# ECAP_0 register map
Vendor: Texas Instruments
Peripheral module from a debugger description file (folder 66AK2G0x_66AK2G1x).
Registers are 32-bit, read-write, reset 0x0 unless marked. A register's access mark holds for its fields unless they carry their own. Offsets are as the file gives them; lines under a group give offsets from that group; [hi:lo] are bit positions; {n}, {i} and the like mark numbered series; 'fields as' and 'values as' point back to an identical list; <NAME> marks a mode.

## ECAP_0
0x00 PWMSS_ECAP_TSCNT
  [31:0] TSCNT — Active 32 bit-counter register that is used as the capture time-base
0x04 PWMSS_ECAP_CNTPHS
  [31:0] CNTPHS — Counter phase value register that can be programmed for phase lag/lead. This register shadows TSCNT and is loaded into
0x08 PWMSS_ECAP_CAP1
  [31:0] CAP1 — This register can be loaded (written) by the following.
0x0C PWMSS_ECAP_CAP2
  [31:0] CAP2 — This register can be loaded (written) by the following.
0x10 PWMSS_ECAP_CAP3
  [31:0] CAP3 — In CMP mode, this is a time-stamp capture register. In APWM mode, this is the period shadow (APRD) register. User SW updates the PWM period value through this register. In this mode, CAP3 shadows CAP1.
0x14 PWMSS_ECAP_CAP4
  [31:0] CAP4 — In CMP mode, this is a time-stamp capture register. In APWM mode, this is the compare shadow (ACMP) register. User SW updates the PWM compare value through this register. In this mode, CAP4 shadows CAP2.
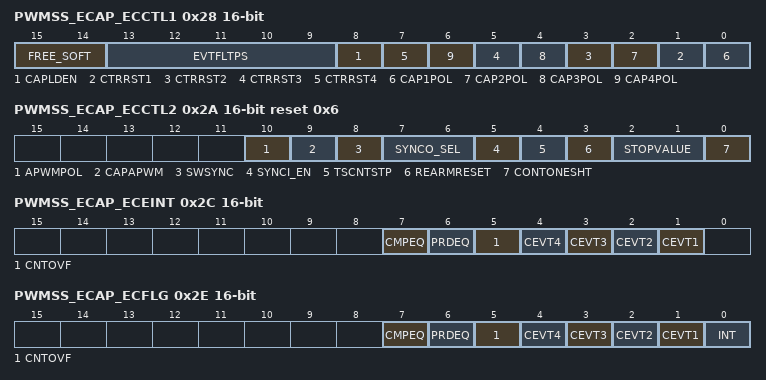
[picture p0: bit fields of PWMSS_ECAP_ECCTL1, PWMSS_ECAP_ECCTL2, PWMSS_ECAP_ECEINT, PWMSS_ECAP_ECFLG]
0x28 PWMSS_ECAP_ECCTL1 16-bit
  [15:14] FREE_SOFT — Emulation Control
  [13:9] EVTFLTPS — Event Filter prescale select:
  [8] CAPLDEN — Enable Loading of
  [2n-1] CTRRST{n} (n=1..4) — Counter Reset on Capture Event {n}
  [2n-2] CAP{n}POL (n=1..4) — Capture Event {n} Polarity select
0x2A PWMSS_ECAP_ECCTL2 16-bit access per field reset 0x6
  [10] APWMPOL rw — APWM output polarity select. This is applicable only in APWM operating mode 0h = Output is active high (Compare value defines high time) 1h = Output is active low (Compare value defines low time)
  [9] CAPAPWM rw — CAP/APWM operating mode select 0h = ECAP module operates in capture mode. This mode forces the following configuration. 1. Inhibits TSCNT resets via TSCNT = PRD event. 2. Inhibits shadow loads on PWMSS_ECAP_CAP1 and PWMSS_ECAP_CAP2 registers. 3. Permits user to enable PWMSS_ECAP_CAP1- PWMSS_ECAP_CAP4 register load. (d) ECAP input / APWM output pin operates as a capture input.
  [8] SWSYNC rw — Software-forced Counter (TSCNT) Synchronizing. This provides a convenient software method to synchronize some or all ECAP time bases. In APWM mode, the synchronizing can also be done via the TSCNT = PRD event. Note: Selection TSCNT = PRD is meaningful only in APWM mode. However, you can choose it in CAP mode if you find doing so useful.
  [7:6] SYNCO_SEL rw — Sync-Out Select
  [5] SYNCI_EN rw
  [4] TSCNTSTP rw — Time Stamp (TSCNT) Counter Stop (freeze) Control 0h = TSCNT stopped 1h = TSCNT free-running
  [3] REARMRESET rw — One-Shot Re-Arming Control, that is, wait for stop trigger. Note: The re-arm function is valid in one shot or continuous mode. 0h = Has no effect (reading always returns a 0) 1h = Arms the one-shot sequence as follows: 1) Resets the Mod4 counter to zero. 2) Unfreezes the Mod4 counter. 3) Enables capture register loads.
  [2:1] STOPVALUE rw — Stop value for one-shot mode. This is the number (between 1 and 4) of captures allowed to occur before the CAP (1 through 4) registers are frozen, that is, capture sequence is stopped. Wrap value for continuous mode. This is the number (between 1 and 4) of the capture register in which the circular buffer wraps around and starts again. Notes: STOPVALUE is compared to Mod4 counter and, when equal, the following two actions occur. (1) Mod4 counter is stopped (frozen). (2) Capture register loads are inhibited. In one-shot mode, further interrupt events are blocked until re-armed. 0h = Stop after Capture Event 1 in one-shot mode. Wrap after Capture Event 1 in continuous mode. 1h = Stop after Capture Event 2 in one-shot mode. Wrap after Capture Event 2 in continuous mode. 2h = Stop after Capture Event 3 in one-shot mode. Wrap after Capture Event 3 in continuous mode. 3h = Stop after Capture Event 4 in one-shot mode. Wrap after Capture Event 4 in continuous mode.
  [0] CONTONESHT rw — Continuous or one-shot mode control (applicable only in capture mode) 0h = Operate in continuous mode 1h = Operate in one-shot mode
0x2C PWMSS_ECAP_ECEINT 16-bit access per field
  [7] CMPEQ rw — Counter Equal Compare Interrupt Enable. 0h = Disable Compare Equal as an Interrupt source. 1h = Enable Compare Equal as an Interrupt source.
  [6] PRDEQ rw — Counter Equal Period Interrupt Enable. 0h = Disable Period Equal as an Interrupt source. 1h = Enable Period Equal as an Interrupt source.
  [5] CNTOVF rw — Counter Overflow Interrupt Enable. 0h = Disable counter Overflow as an Interrupt source. 1h = Enable counter Overflow as an Interrupt source.
  [4] CEVT4 rw — Capture Event 4 Interrupt Enable. 0h = Disable Capture Event 4 as an Interrupt source. 1h = Enable Capture Event 4 as an Interrupt source.
  [3] CEVT3 rw — Capture Event 3 Interrupt Enable. 0h = Disable Capture Event 3 as an Interrupt source. 1h = Enable Capture Event 3 as an Interrupt source.
  [2] CEVT2 rw — Capture Event 2 Interrupt Enable. 0h = Disable Capture Event 2 as an Interrupt source. 1h = Enable Capture Event 2 as an Interrupt source.
  [1] CEVT1 rw — Capture Event 1 Interrupt Enable . 0h = Disable Capture Event 1 as an Interrupt source. 1h = Enable Capture Event 1 as an Interrupt source.
0x2E PWMSS_ECAP_ECFLG 16-bit ro
  [7] CMPEQ — Compare Equal Compare Status Flag. This flag is only active in APWM mode. 0h = Indicates no event occurred 1h = Indicates the counter (TSCNT) reached the compare register value (ACMP)
  [6] PRDEQ — Counter Equal Period Status Flag. This flag is only active in APWM mode. 0h = Indicates no event occurred 1h = Indicates the counter (TSCNT) reached the period register value (APRD) and was reset.
  [5] CNTOVF — Counter Overflow Status Flag. This flag is active in CAP and APWM mode. 0h = Indicates no event occurred. 1h = Indicates the counter (TSCNT) has made the transition from FFFF FFFFh to 0000 0000h
  [4] CEVT4 — Capture Event 4 Status Flag This flag is only active in CAP mode. 0h = Indicates no event occurred 1h = Indicates the fourth event occurred at ECAPn pin
  [3] CEVT3 — Capture Event 3 Status Flag. This flag is active only in CAP mode. 0h = Indicates no event occurred. 1h = Indicates the third event occurred at ECAPn pin.
  [2] CEVT2 — Capture Event 2 Status Flag. This flag is only active in CAP mode. 0h = Indicates no event occurred. 1h = Indicates the second event occurred at ECAPn pin.
  [1] CEVT1 — Capture Event 1 Status Flag. This flag is only active in CAP mode. 0h = Indicates no event occurred. 1h = Indicates the first event occurred at ECAPn pin.
  [0] INT — Global Interrupt Status Flag 0h = Indicates no interrupt generated. 1h = Indicates that an interrupt was generated.
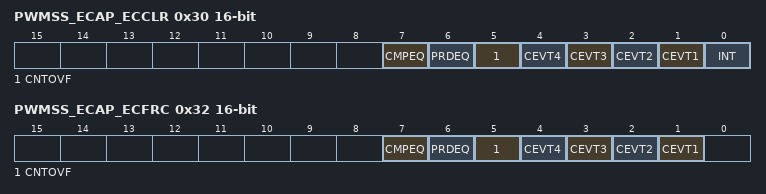
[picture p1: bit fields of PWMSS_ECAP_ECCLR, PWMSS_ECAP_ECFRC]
0x30 PWMSS_ECAP_ECCLR 16-bit access per field
  [7] CMPEQ rw — Counter Equal Compare Status Flag 0h = Writing a 0 has no effect. Always reads back a 0 1h = Writing a 1 clears the TSCNT=CMP flag condition
  [6] PRDEQ rw — Counter Equal Period Status Flag 0h = Writing a 0 has no effect. Always reads back a 0 1h = Writing a 1 clears the TSCNT=PRD flag condition
  [5] CNTOVF rw — Counter Overflow Status Flag 0h = Writing a 0 has no effect. Always reads back a 0 1h = Writing a 1 clears the CNTOVF flag condition
  [4] CEVT4 rw — Capture Event 4 Status Flag 0h = Writing a 0 has no effect. Always reads back a 0. 1h = Writing a 1 clears the CEVT3 flag condition.
  [3] CEVT3 rw — Capture Event 3 Status Flag 0h = Writing a 0 has no effect. Always reads back a 0. 1h = Writing a 1 clears the CEVT3 flag condition.
  [2] CEVT2 rw — Capture Event 2 Status Flag 0h = Writing a 0 has no effect. Always reads back a 0. 1h = Writing a 1 clears the CEVT2 flag condition.
  [1] CEVT1 rw — Capture Event 1 Status Flag 0h = Writing a 0 has no effect. Always reads back a 0. 1h = Writing a 1 clears the CEVT1 flag condition.
  [0] INT rw — Global Interrupt Clear Flag 0h = Writing a 0 has no effect. Always reads back a 0. 1h = Writing a 1 clears the INT flag and enable further interrupts to be generated if any of the event flags are set to 1.
0x32 PWMSS_ECAP_ECFRC 16-bit access per field
  [7] CMPEQ rw — Force Counter Equal Compare Interrupt 0h = No effect. Always reads back a 0. 1h = Writing a 1 sets the TSCNT=CMP flag bit.
  [6] PRDEQ rw — Force Counter Equal Period Interrupt 0h = No effect. Always reads back a 0. 1h = Writing a 1 sets the TSCNT=PRD flag bit.
  [5] CNTOVF rw — Force Counter Overflow 0h = No effect. Always reads back a 0. 1h = Writing a 1 to this bit sets the CNTOVF flag bit.
  [4] CEVT4 rw — Force Capture Event 4 0h = No effect. Always reads back a 0. 1h = Writing a 1 sets the CEVT4 flag bit
  [3] CEVT3 rw — Force Capture Event 3 0h = No effect. Always reads back a 0. 1h = Writing a 1 sets the CEVT3 flag bit
  [2] CEVT2 rw — Force Capture Event 2 0h = No effect. Always reads back a 0. 1h = Writing a 1 sets the CEVT2 flag bit.
  [1] CEVT1 rw — Force Capture Event 1 0h = No effect. Always reads back a 0. 1h = Writing a 1 sets the CEVT1 flag bit.
0x5C PWMSS_ECAP_PID ro reset 0x44D22100
  [31:0] REVISION — TI internal data. Identifies revision of peripheral.
